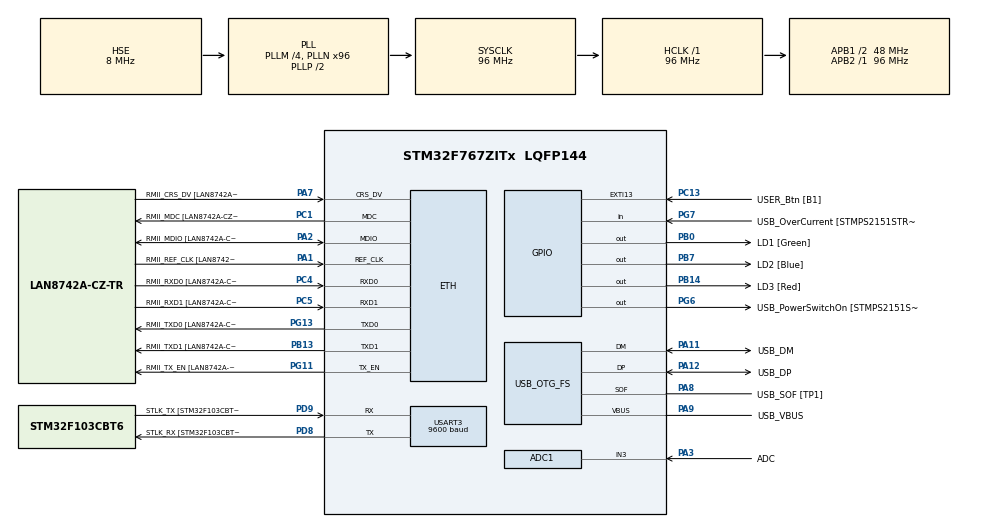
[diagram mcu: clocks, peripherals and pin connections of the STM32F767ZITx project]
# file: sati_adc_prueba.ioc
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Mcu.Family=STM32F7
RCC.CortexFreq_Value=96000000
PG6.Signal=GPIO_Output
PB14.GPIO_Label=LD3 [Red]
PG6.GPIO_Label=USB_PowerSwitchOn [STMPS2151STR_EN]
PA14.GPIO_Label=TCK
RCC.SYSCLKSourceVirtual=RCC_SYSCLKSOURCE_PLLCLK
PA11.Mode=Device_Only
PB0.GPIO_Label=LD1 [Green]
PC14/OSC32_IN.Mode=LSE-External-Oscillator
PC5.Mode=RMII
PC13.GPIO_Label=USER_Btn [B1]
PB13.GPIO_Label=RMII_TXD1 [LAN8742A-CZ-TR_TXD1]
PB13.Signal=ETH_TXD1
PG13.Signal=ETH_TXD0
PD9.Mode=Asynchronous
PG11.Signal=ETH_TX_EN
RCC.SYSCLKSource=RCC_SYSCLKSOURCE_PLLCLK
ProjectManager.StackSize=0x400
USART3.VirtualMode-Asynchronous=VM_ASYNC
PA12.Signal=USB_OTG_FS_DP
USART3.BaudRate=9600
ETH.PHY_Value=0
PH0/OSC_IN.Mode=HSE-External-Clock-Source
RCC.HCLKFreq_Value=96000000
SH.ADCx_IN3.0=ADC1_IN3,IN3
RCC.APB2TimFreq_Value=96000000
PH1/OSC_OUT.Signal=RCC_OSC_OUT
PD8.Signal=USART3_TX
RCC.AHBFreq_Value=96000000
RCC.HSE_VALUE=8000000
RCC.PLLMUL=RCC_PLL_MUL9
PC4.GPIO_Label=RMII_RXD0 [LAN8742A-CZ-TR_RXD0]
PA14.Mode=Serial_Wire
PA10.GPIO_Label=USB_ID
PB7.Signal=GPIO_Output
PA8.Signal=USB_OTG_FS_SOF
PG13.Mode=RMII
ETH.PHY_Name=LAN8742A_PHY_ADDRESS
PH1/OSC_OUT.Mode=HSE-External-Clock-Source
PB7.GPIO_Label=LD2 [Blue]
Mcu.Package=LQFP144
PC14/OSC32_IN.Signal=RCC_OSC32_IN
PA2.GPIO_Label=RMII_MDIO [LAN8742A-CZ-TR_MDIO]
PA10.Signal=USB_OTG_FS_ID
USB_OTG_FS.VirtualMode=Device_Only
RCC.APB1TimFreq_Value=96000000
PG11.GPIO_Label=RMII_TX_EN [LAN8742A-CZ-TR_TXEN]
PC5.Signal=ETH_RXD1
PB13.Mode=RMII
PC4.Mode=RMII
PA3.Signal=ADCx_IN3
PB3.GPIO_Label=SWO
PA7.Mode=RMII
PG7.Signal=GPIO_Input
PD9.GPIO_Label=STLK_TX [STM32F103CBT6_PA2]
PC13.Signal=GPXTI13
PA9.GPIO_Label=USB_VBUS
PC4.Signal=ETH_RXD0
PA11.GPIO_Label=USB_DM
PD9.Signal=USART3_RX
RCC.APB1CLKDivider=RCC_HCLK_DIV2
PG13.GPIO_Label=RMII_TXD0 [LAN8742A-CZ-TR_TXD0]
ETH.PhyAddress=0
PA12.GPIO_Label=USB_DP
PD8.GPIO_Label=STLK_RX [STM32F103CBT6_PA3]
PA13.Signal=SYS_JTMS-SWDIO
PA9.Mode=Activate_VBUS
PA8.GPIO_Label=USB_SOF [TP1]
ProjectManager.TargetToolchain=STM32CubeIDE
PA9.Signal=USB_OTG_FS_VBUS
ADC1.Channel-1\#ChannelRegularConversion=ADC_CHANNEL_3
RCC.USBFreq_Value=48000000
PD8.Mode=Asynchronous
PA1.Signal=ETH_REF_CLK
PB14.Signal=GPIO_Output
board=NUCLEO-F767ZI
RCC.VCOOutputFreq_Value=192000000
PH0/OSC_IN.Signal=RCC_OSC_IN
RCC.APB2Freq_Value=96000000
PA1.Mode=RMII
RCC.PRESCALERUSB=RCC_USBCLKSOURCE_PLL_DIV1_5
PG7.GPIO_Label=USB_OverCurrent [STMPS2151STR_FAULT]
PA1.GPIO_Label=RMII_REF_CLK [LAN8742A-CZ-TR_REFCLK0]
PC1.GPIO_Label=RMII_MDC [LAN8742A-CZ-TR_MDC]
PA13.Mode=Serial_Wire
Mcu.Name=STM32F767ZITx
PA2.Signal=ETH_MDIO
PA13.GPIO_Label=TMS
RCC.48MHZClocksFreq_Value=24000000
PB3.Signal=SYS_JTDO-SWO
ADC1.SamplingTime-1\#ChannelRegularConversion=ADC_SAMPLETIME_3CYCLES
RCC.SYSCLKFreq_VALUE=96000000
ETH.MediaInterface=ETH_MEDIA_INTERFACE_RMII
PA7.GPIO_Label=RMII_CRS_DV [LAN8742A-CZ-TR_CRS_DV]
ADC1.master=1
PA12.Mode=Device_Only
PC5.GPIO_Label=RMII_RXD1 [LAN8742A-CZ-TR_RXD1]
PC15/OSC32_OUT.Mode=LSE-External-Oscillator
ADC1.Rank-1\#ChannelRegularConversion=1
PG11.Mode=RMII
PA11.Signal=USB_OTG_FS_DM
PA14.Signal=SYS_JTCK-SWCLK
ProjectManager.HeapSize=0x200
RCC.HSI_VALUE=16000000
PH0/OSC_IN.GPIO_Label=MCO [STM32F103CBT6_PA8]
RCC.PLLQ=4
NVIC.PriorityGroup=NVIC_PRIORITYGROUP_4
ADC1.NbrOfConversionFlag=1
RCC.PLLM=4
RCC.PLLN=96
PA2.Mode=RMII
PC15/OSC32_OUT.Signal=RCC_OSC32_OUT
PA8.Mode=Activate_SOF_FS
RCC.APB1Freq_Value=48000000
PB0.Signal=GPIO_Output
PC1.Signal=ETH_MDC
PC1.Mode=RMII
PA3.GPIO_Label=ADC
PA7.Signal=ETH_CRS_DV

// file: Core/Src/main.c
/* USER CODE BEGIN Header */
/**
  **************************
  * @file           : main.c
  * @brief          : Main program body
  **************************
  * @attention
  *
  * <h2><center>&copy; Copyright (c) 2021 STMicroelectronics.
  * All rights reserved.</center></h2>
  *
  * This software component is licensed by ST under BSD 3-Clause license,
  * the "License"; You may not use this file except in compliance with the
  * License. You may obtain a copy of the License at:
  *                        opensource.org/licenses/BSD-3-Clause
  *
  **************************
  */
/* USER CODE END Header */
#include "main.h"
#include "adc.h"
#include "eth.h"
#include "usart.h"
#include "usb_otg.h"
#include "gpio.h"

/* USER CODE BEGIN Includes */
#include <string.h>
#include <stdio.h>
/* USER CODE END Includes */

void SystemClock_Config(void);

int main(void)
{
  /* USER CODE BEGIN 1 */
	uint16_t POT;//12 bit ADC reading variable
	char msg[45];//PRINT UART
	//int ACT_1 = 0;//BANDERA ACTUADOR
  /* USER CODE END 1 */

  /* MCU Configuration--------------------------------------------------------*/

  /* Reset of all peripherals, Initializes the Flash interface and the Systick. */
  HAL_Init();

  /* Configure the system clock */
  SystemClock_Config();

  /* Initialize all configured peripherals */
  MX_GPIO_Init();
  MX_ETH_Init();
  MX_USART3_UART_Init();
  MX_USB_OTG_FS_PCD_Init();
  MX_ADC1_Init();

  /* Infinite loop */
  /* USER CODE BEGIN WHILE */
  while (1)
  {
	  //Set GPIO pin high
	  //HAL_GPIO_WritePin(GPIOA, GPIO_PIN_10, GPIO_PIN_SET);

	  //Get ADC value
	  HAL_ADC_Start(&hadc1);
	  HAL_ADC_PollForConversion(&hadc1, HAL_MAX_DELAY);
	  POT = HAL_ADC_GetValue(&hadc1);
	  //Set GPIO pin low
	  //HAL_GPIO_WritePin(GPIOA, GPIO_PIN_10, GPIO_PIN_RESET);

	  //Convert to string and print
	  sprintf(msg,"VALORaaaaa: %hu\r\n",POT);
	  HAL_UART_Transmit(&huart3, (uint8_t*)msg, strlen(msg), HAL_MAX_DELAY);

	  HAL_Delay(1000);
    /* USER CODE END WHILE */

  }
}

void SystemClock_Config(void)
{
  RCC_OscInitTypeDef RCC_OscInitStruct = {0};
  RCC_ClkInitTypeDef RCC_ClkInitStruct = {0};
  RCC_PeriphCLKInitTypeDef PeriphClkInitStruct = {0};

  /** Configure LSE Drive Capability
  */
  HAL_PWR_EnableBkUpAccess();
  /** Configure the main internal regulator output voltage
  */
  __HAL_RCC_PWR_CLK_ENABLE();
  __HAL_PWR_VOLTAGESCALING_CONFIG(PWR_REGULATOR_VOLTAGE_SCALE3);
  /** Initializes the RCC Oscillators according to the specified parameters
  * in the RCC_OscInitTypeDef structure.
  */
  RCC_OscInitStruct.OscillatorType = RCC_OSCILLATORTYPE_HSE;
  RCC_OscInitStruct.HSEState = RCC_HSE_BYPASS;
  RCC_OscInitStruct.PLL.PLLState = RCC_PLL_ON;
  RCC_OscInitStruct.PLL.PLLSource = RCC_PLLSOURCE_HSE;
  RCC_OscInitStruct.PLL.PLLM = 4;
  RCC_OscInitStruct.PLL.PLLN = 96;
  RCC_OscInitStruct.PLL.PLLP = RCC_PLLP_DIV2;
  RCC_OscInitStruct.PLL.PLLQ = 4;
  if (HAL_RCC_OscConfig(&RCC_OscInitStruct) != HAL_OK)
  {
    Error_Handler();
  }
  /** Activate the Over-Drive mode
  */
  if (HAL_PWREx_EnableOverDrive() != HAL_OK)
  {
    Error_Handler();
  }
  /** Initializes the CPU, AHB and APB buses clocks
  */
  RCC_ClkInitStruct.ClockType = RCC_CLOCKTYPE_HCLK|RCC_CLOCKTYPE_SYSCLK
                              |RCC_CLOCKTYPE_PCLK1|RCC_CLOCKTYPE_PCLK2;
  RCC_ClkInitStruct.SYSCLKSource = RCC_SYSCLKSOURCE_PLLCLK;
  RCC_ClkInitStruct.AHBCLKDivider = RCC_SYSCLK_DIV1;
  RCC_ClkInitStruct.APB1CLKDivider = RCC_HCLK_DIV2;
  RCC_ClkInitStruct.APB2CLKDivider = RCC_HCLK_DIV1;

  if (HAL_RCC_ClockConfig(&RCC_ClkInitStruct, FLASH_LATENCY_3) != HAL_OK)
  {
    Error_Handler();
  }
  PeriphClkInitStruct.PeriphClockSelection = RCC_PERIPHCLK_USART3|RCC_PERIPHCLK_CLK48;
  PeriphClkInitStruct.Usart3ClockSelection = RCC_USART3CLKSOURCE_PCLK1;
  PeriphClkInitStruct.Clk48ClockSelection = RCC_CLK48SOURCE_PLL;
  if (HAL_RCCEx_PeriphCLKConfig(&PeriphClkInitStruct) != HAL_OK)
  {
    Error_Handler();
  }
}

void Error_Handler(void)
{
}

/************************ (C) COPYRIGHT STMicroelectronics *****END OF FILE****/
